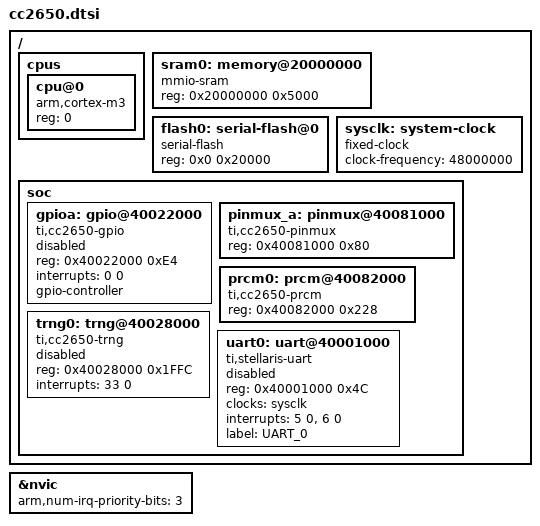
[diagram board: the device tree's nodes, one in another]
/*
 * SPDX-License-Identifier: Apache-2.0
 *
 * Device Tree include file for CC2650 SoC from Texas Instruments.
 */

#include "armv7-m.dtsi"

/ {
	cpus {
		#address-cells = <1>;
		#size-cells = <0>;

		cpu@0 {
			device_type = "cpu";
			compatible = "arm,cortex-m3";
			reg = <0>;
		};
	};

	sram0: memory@20000000 {
		compatible = "mmio-sram";
		reg = <0x20000000 0x5000>;
	};

	flash0: serial-flash@0 {
		compatible = "serial-flash";
		reg = <0x0 0x20000>;
	};

	sysclk: system-clock {
		compatible = "fixed-clock";
		clock-frequency = <48000000>;
		#clock-cells = <0>;
	};

	soc {
		gpioa: gpio@40022000 {
			compatible = "ti,cc2650-gpio";
			reg = <0x40022000 0xE4>;
			interrupts = <0 0>;
			status = "disabled";

			gpio-controller;
			#gpio-cells = <1>;
		};

		pinmux_a: pinmux@40081000 {
			compatible = "ti,cc2650-pinmux";
			reg = <0x40081000 0x80>;
		};

		prcm0: prcm@40082000 {
			compatible = "ti,cc2650-prcm";
			reg = <0x40082000 0x228>;
		};

		trng0: trng@40028000 {
			compatible = "ti,cc2650-trng";
			reg = <0x40028000 0x1FFC>;
			interrupts = <33 0>;
			status = "disabled";
		};

		uart0: uart@40001000 {
			compatible = "ti,stellaris-uart";
			reg = <0x40001000 0x4C>;
			clocks = <&sysclk>;
			interrupts = <5 0>, <6 0>;
			status = "disabled";
			label = "UART_0";
		};
	};
};

&nvic {
	arm,num-irq-priority-bits = <3>;
};
